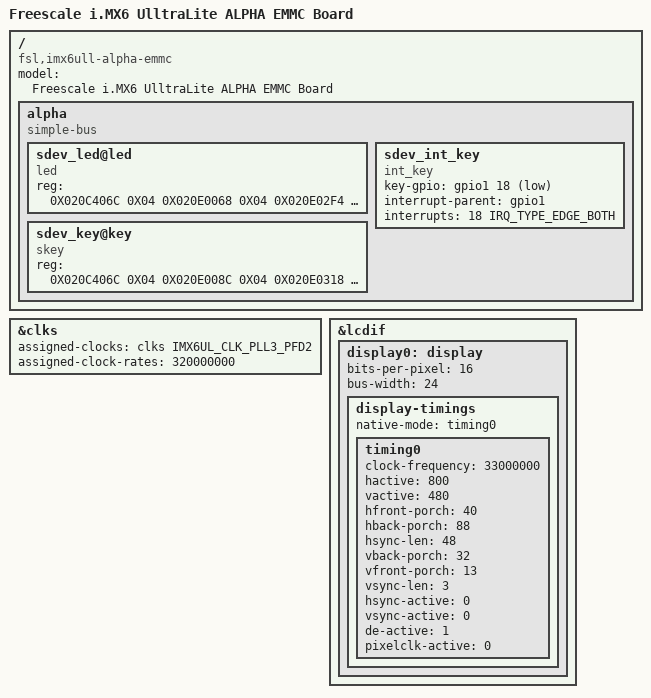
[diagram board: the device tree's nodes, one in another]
/*
 * Copyright (C) 2016 Freescale Semiconductor, Inc.
 *
 * This file is dual-licensed: you can use it either under the terms
 * of the GPL or the X11 license, at your option. Note that this dual
 * licensing only applies to this file, and not this project as a
 * whole.
 *
 *  a) This file is free software; you can redistribute it and/or
 *     modify it under the terms of the GNU General Public License
 *     version 2 as published by the Free Software Foundation.
 *
 *     This file is distributed in the hope that it will be useful,
 *     but WITHOUT ANY WARRANTY; without even the implied warranty of
 *     MERCHANTABILITY or FITNESS FOR A PARTICULAR PURPOSE.  See the
 *     GNU General Public License for more details.
 *
 * Or, alternatively,
 *
 *  b) Permission is hereby granted, free of charge, to any person
 *     obtaining a copy of this software and associated documentation
 *     files (the "Software"), to deal in the Software without
 *     restriction, including without limitation the rights to use,
 *     copy, modify, merge, publish, distribute, sublicense, and/or
 *     sell copies of the Software, and to permit persons to whom the
 *     Software is furnished to do so, subject to the following
 *     conditions:
 *
 *     The above copyright notice and this permission notice shall be
 *     included in all copies or substantial portions of the Software.
 *
 *     THE SOFTWARE IS PROVIDED "AS IS", WITHOUT WARRANTY OF ANY KIND,
 *     EXPRESS OR IMPLIED, INCLUDING BUT NOT LIMITED TO THE WARRANTIES
 *     OF MERCHANTABILITY, FITNESS FOR A PARTICULAR PURPOSE AND
 *     NONINFRINGEMENT. IN NO EVENT SHALL THE AUTHORS OR COPYRIGHT
 *     HOLDERS BE LIABLE FOR ANY CLAIM, DAMAGES OR OTHER LIABILITY,
 *     WHETHER IN AN ACTION OF CONTRACT, TORT OR OTHERWISE, ARISING
 *     FROM, OUT OF OR IN CONNECTION WITH THE SOFTWARE OR THE USE OR
 *     OTHER DEALINGS IN THE SOFTWARE.
 */

/dts-v1/;

#include "imx6ull.dtsi"
#include "imx6ull-alpha-emmc.dtsi"
#include "version.dtsi"

/ {
	model = "Freescale i.MX6 UlltraLite ALPHA EMMC Board";
	compatible = "fsl,imx6ull-alpha-emmc", "fsl,imx6ull";

    alpha {
        #address-cells = <1>;
        #size-cells = <1>;
        compatible = "simple-bus";
        // GPIO1_IO03
        // 0X020C406C CCM_CCGR1
        // 0X020E0068 SW_MUX_CTL_PAD_GPIO1_IO03 SW MUX Control Register (IOMUXC_SW_MUX_CTL_PAD_GPIO1_IO03)
        // 0X020E02F4 SW_PAD_CTL_PAD_GPIO1_IO03 SW PAD Control Register (IOMUXC_SW_PAD_CTL_PAD_GPIO1_IO03)
        // 0X0209C000 GPIO data register (GPIO1_DR)
        // 0X0209C004 GPIO direction register (GPIO1_GDIR)
        // 0X0209C008 GPIO pad status register (GPIO1_PSR)
        // 0X0209C00C GPIO interrupt configuration register1 (GPIO1_ICR1) 
        // 0X0209C010 GPIO interrupt configuration register2 (GPIO1_ICR2) 
        // 0X0209C014 GPIO interrupt mask register (GPIO1_IMR)
        // 0X0209C018 GPIO interrupt status register (GPIO1_ISR) 
        // 0X0209C01C GPIO edge select register (GPIO1_EDGE_SEL) 
        sdev_led@led {
            #address-cells = <1>;
            #size-cells = <1>;
            compatible = "led";
            status = "okay";
            reg = < 0X020C406C 0X04 /* CCM_CCGR1_BASE */
                    0X020E0068 0X04 /* SW_MUX_GPIO1_IO03_BASE */
                    0X020E02F4 0X04 /* SW_PAD_GPIO1_IO03_BASE */
                    0X0209C000 0X04 /* GPIO1_DR_BASE */
                    0X0209C004 0X04 >; /* GPIO1_GDIR_BASE */
        };
        // GPIO1_IO18
        // 0X020C406C CCM_CCGR1
        // 0X020E008C SW_MUX_CTL_PAD_UART1_CTS_B SW MUX Control Register (IOMUXC_SW_MUX_CTL_PAD_UART1_CTS_B)
        // 0X020E0318 SW_PAD_CTL_PAD_UART1_CTS_B SW PAD Control Register (IOMUXC_SW_PAD_CTL_PAD_UART1_CTS_B)
        // 0X0209C000 GPIO data register (GPIO1_DR)
        // 0X0209C004 GPIO direction register (GPIO1_GDIR)
        // 0X0209C008 GPIO pad status register (GPIO1_PSR)
        // 0X0209C00C GPIO interrupt configuration register1 (GPIO1_ICR1) 
        // 0X0209C010 GPIO interrupt configuration register2 (GPIO1_ICR2) 
        // 0X0209C014 GPIO interrupt mask register (GPIO1_IMR)
        // 0X0209C018 GPIO interrupt status register (GPIO1_ISR) 
        // 0X0209C01C GPIO edge select register (GPIO1_EDGE_SEL) 
        sdev_key@key {
            #address-cells = <1>;
            #size-cells = <1>;
            compatible = "skey";
            status = "okay";
            reg = < 0X020C406C 0X04 /* CCM_CCGR1_BASE */
                    0X020E008C 0X04 /* SW_MUX_CTL_PAD_UART1_CTS_B */
                    0X020E0318 0X04 /* SW_PAD_CTL_PAD_UART1_CTS_B */
                    0X0209C000 0X04 /* GPIO1_DR_BASE */
                    0X0209C004 0X04 /* GPIO1_GDIR_BASE */
                    0X0209C008 0X04 /* GPIO1_PSR_BASE */
                    >; 
        };

        sdev_int_key {
            #address-cells = <1>;
            #size-cells = <1>;
            compatible = "int_key";
            status = "okay";
            key-gpio = <&gpio1 18 GPIO_ACTIVE_LOW>; /* KEY0 GPIO1_IO18*/
            interrupt-parent = <&gpio1>;
            //gpio1中#interrupt-cells = <2>;
            interrupts = <18 IRQ_TYPE_EDGE_BOTH>; /* FALLING RISING */
        };
    };
};

&clks {
	assigned-clocks = <&clks IMX6UL_CLK_PLL3_PFD2>;
	assigned-clock-rates = <320000000>;
};

/** LCD时序相关参数以及其他的叫法
 * |             param           | alias | fb_videomode | display-timings | ATK-MD0430R-800480 | unit |
 * | --------------------------- | ----- | ------------ | --------------- | ------------------ | ---- |
 * | HOZVAL(水平显示区域)          |  thd  |     xres     |      hactive    |        800         | tCLK |
 * | HSPW(horizontal sync width) |  thp  |   hsync_len  |     hsync-len   |        48          | tCLK |
 * | HBP(horizontal back porch)  |  thb  |  left_margin |    hback-porch  |        88          | tCLK |
 * | HFP(horizontal front porth) |  thf  | right_margin |   hfront-porch  |        40          | tCLK |
 * | LINE(垂直显示区域)            |  tvd  |     yres     |     vactive     |        480         | th   |
 * | VSPW(vertical sync width)   |  tvp  |  vsync_len   |    vsync-len    |        3           | th   |
 * | VBP(vertical back porch)    |  tvb  | upper_margin |   vback-porch   |        32          | th   |
 * | VFP(vertical front porch)   |  tvf  | lower_margin |   vfront-porch  |        13          | th   |
 * | pixclock                    |   -   |  pixclock    | clock-frequency |        31          | MHz  |
 *
 * 显示  1 帧：clknum = (VSPW+VBP+LINE+VFP)*(HSPW+HBP+HOZVAL+HFP)=(3+32+480+13)*(48+88+800+40)=515328
 * 显示 60 帧：clknum = (VSPW+VBP+LINE+VFP)*(HSPW+HBP+HOZVAL+HFP)*60==515328*60=30919680≈31M
 * 需要注意的是：
 *           （1）uboot中的这个像素时钟参数不是频率，而是每个像素时钟周期的长度，单位为皮秒。pixclock=(1/像素时钟数)*10^12
 *           （2）至少uboot 2019.04这个版本中的LCD实际并不是使用的设备树。
 */

&lcdif {
	display0: display {
		bits-per-pixel = <16>;
		bus-width = <24>;

		display-timings {
			native-mode = <&timing0>;
			timing0: timing0 {
			clock-frequency = <33000000>;
			hactive = <800>;
			vactive = <480>;
			hfront-porch = <40>;
			hback-porch = <88>;
			hsync-len = <48>;
			vback-porch = <32>;
			vfront-porch = <13>;
			vsync-len = <3>;

			hsync-active = <0>;
			vsync-active = <0>;
			de-active = <1>;
			pixelclk-active = <0>;
			};
		};
	};
};

